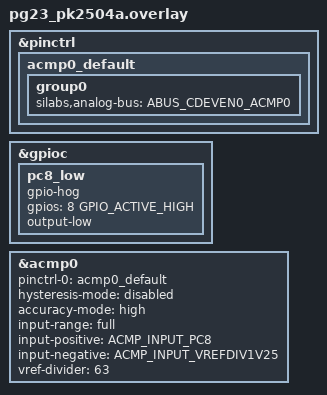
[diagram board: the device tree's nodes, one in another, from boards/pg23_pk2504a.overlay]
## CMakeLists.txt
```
# SPDX-License-Identifier: Apache-2.0

cmake_minimum_required(VERSION 3.20.0)

find_package(Zephyr REQUIRED HINTS $ENV{ZEPHYR_BASE})
project(comparator)

target_sources(app PRIVATE src/main.c)

zephyr_library_include_directories(${ZEPHYR_BASE}/samples/comparator)
```

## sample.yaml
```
sample:
  name: Comparator
  description: Similar to the Silabs' SOC Blinky sample, implements a simple custom
              GATT service controlling the state of the LED (ON/OFF)
              and sending notifications to subscribed clients when the button state changes.
tests:
  sample.comparator:
    harness: comparator
    integration_platforms:
      - xg24_dk2601b
    tags:
      - led
      - gpio
    build_only: true
```

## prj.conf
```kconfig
CONFIG_GPIO=y
CONFIG_PM_DEVICE=y
CONFIG_PM_DEVICE_RUNTIME=y
CONFIG_COMPARATOR=y
```

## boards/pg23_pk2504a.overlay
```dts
/*
 * Copyright (c) 2026 Silicon Laboratories Inc.
 *
 * SPDX-License-Identifier: Apache-2.0
 */

#include <zephyr/dt-bindings/gpio/gpio.h>
#include <zephyr/dt-bindings/comparator/silabs-acmp.h>
#include <zephyr/dt-bindings/pinctrl/silabs/xg23-pinctrl.h>

&pinctrl {
	acmp0_default: acmp0_default {
		group0 {
			silabs,analog-bus = <ABUS_CDEVEN0_ACMP0>;
		};
	};
};

&gpioc {
	pc8_low: pc8_low {
		gpio-hog;
		gpios = <8 GPIO_ACTIVE_HIGH>;
		output-low;
	};
};

&acmp0 {
	pinctrl-0 = <&acmp0_default>;
	pinctrl-names = "default";
	status = "okay";

	hysteresis-mode = "disabled";
	accuracy-mode = "high";
	input-range = "full";
	input-positive = <ACMP_INPUT_PC8>;
	input-negative = <ACMP_INPUT_VREFDIV1V25>;
	vref-divider = <63>;
};
```

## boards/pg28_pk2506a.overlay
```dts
/*
 * Copyright (c) 2026 Silicon Laboratories Inc.
 *
 * SPDX-License-Identifier: Apache-2.0
 */

#include <zephyr/dt-bindings/gpio/gpio.h>
#include <zephyr/dt-bindings/comparator/silabs-acmp.h>
#include <zephyr/dt-bindings/pinctrl/silabs/xg28-pinctrl.h>

&pinctrl {
	acmp0_default: acmp0_default {
		group0 {
			silabs,analog-bus = <ABUS_CDEVEN0_ACMP0>;
		};
	};
};

&gpioc {
	pc10_low: pc10_low {
		gpio-hog;
		gpios = <10 GPIO_ACTIVE_HIGH>;
		output-low;
	};
};

&acmp0 {
	pinctrl-0 = <&acmp0_default>;
	pinctrl-names = "default";
	status = "okay";

	hysteresis-mode = "disabled";
	accuracy-mode = "high";
	input-range = "full";
	input-positive = <ACMP_INPUT_PC10>;
	input-negative = <ACMP_INPUT_VREFDIV1V25>;
	vref-divider = <63>;
};
```

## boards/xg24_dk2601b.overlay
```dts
/*
 * Copyright (c) 2026 Silicon Laboratories Inc.
 *
 * SPDX-License-Identifier: Apache-2.0
 */

#include <zephyr/dt-bindings/gpio/gpio.h>
#include <zephyr/dt-bindings/comparator/silabs-acmp.h>
#include <zephyr/dt-bindings/pinctrl/silabs/xg24-pinctrl.h>

&pinctrl {
	acmp0_default: acmp0_default {
		group0 {
			silabs,analog-bus = <ABUS_CDODD0_ACMP0>;
		};
	};
};

&gpioc {
	pc3_low: pc3_low {
		gpio-hog;
		gpios = <3 GPIO_ACTIVE_HIGH>;
		output-low;
	};
};

&acmp0 {
	pinctrl-0 = <&acmp0_default>;
	pinctrl-names = "default";
	status = "okay";

	hysteresis-mode = "disabled";
	accuracy-mode = "high";
	input-range = "full";
	input-positive = <ACMP_INPUT_PC3>;
	input-negative = <ACMP_INPUT_VREFDIV1V25>;
	vref-divider = <63>;
};
```

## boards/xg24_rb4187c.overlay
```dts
/*
 * Copyright (c) 2026 Silicon Laboratories Inc.
 *
 * SPDX-License-Identifier: Apache-2.0
 */

#include <zephyr/dt-bindings/gpio/gpio.h>
#include <zephyr/dt-bindings/comparator/silabs-acmp.h>
#include <zephyr/dt-bindings/pinctrl/silabs/xg24-pinctrl.h>

&pinctrl {
	acmp0_default: acmp0_default {
		group0 {
			silabs,analog-bus = <ABUS_BEVEN0_ACMP0>;
		};
	};
};

&gpiob {
	pb2_low: pb2_low {
		gpio-hog;
		gpios = <2 GPIO_ACTIVE_HIGH>;
		output-low;
	};
};

&acmp0 {
	pinctrl-0 = <&acmp0_default>;
	pinctrl-names = "default";
	status = "okay";

	hysteresis-mode = "disabled";
	accuracy-mode = "high";
	input-range = "full";
	input-positive = <ACMP_INPUT_PB2>;
	input-negative = <ACMP_INPUT_VREFDIV1V25>;
	vref-divider = <63>;
};
```

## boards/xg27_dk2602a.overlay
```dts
/*
 * Copyright (c) 2026 Silicon Laboratories Inc.
 *
 * SPDX-License-Identifier: Apache-2.0
 */

#include <zephyr/dt-bindings/gpio/gpio.h>
#include <zephyr/dt-bindings/comparator/silabs-acmp.h>
#include <zephyr/dt-bindings/pinctrl/silabs/xg27-pinctrl.h>

&pinctrl {
	acmp0_default: acmp0_default {
		group0 {
			silabs,analog-bus = <ABUS_CDEVEN0_ACMP0>;
		};
	};
};

&gpioc {
	pc0_low: pc0_low {
		gpio-hog;
		gpios = <0 GPIO_ACTIVE_HIGH>;
		output-low;
	};
};

&acmp0 {
	pinctrl-0 = <&acmp0_default>;
	pinctrl-names = "default";
	status = "okay";

	hysteresis-mode = "disabled";
	accuracy-mode = "high";
	input-range = "full";
	input-positive = <ACMP_INPUT_PC0>;
	input-negative = <ACMP_INPUT_VREFDIV1V25>;
	vref-divider = <63>;
};
```

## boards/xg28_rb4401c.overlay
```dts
/*
 * Copyright (c) 2026 Silicon Laboratories Inc.
 *
 * SPDX-License-Identifier: Apache-2.0
 */

#include <zephyr/dt-bindings/gpio/gpio.h>
#include <zephyr/dt-bindings/comparator/silabs-acmp.h>
#include <zephyr/dt-bindings/pinctrl/silabs/xg28-pinctrl.h>

&pinctrl {
	acmp0_default: acmp0_default {
		group0 {
			silabs,analog-bus = <ABUS_CDEVEN0_ACMP0>;
		};
	};
};

&gpiod {
	pd4_low: pd4_low {
		gpio-hog;
		gpios = <4 GPIO_ACTIVE_HIGH>;
		output-low;
	};
};

&acmp0 {
	pinctrl-0 = <&acmp0_default>;
	pinctrl-names = "default";
	status = "okay";

	hysteresis-mode = "disabled";
	accuracy-mode = "high";
	input-range = "full";
	input-positive = <ACMP_INPUT_PD4>;
	input-negative = <ACMP_INPUT_VREFDIV1V25>;
	vref-divider = <63>;
};
```

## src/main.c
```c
/*
 * Copyright (c) 2026 Silicon Laboratories Inc.
 * Copyright (c) 2015-2016 Intel Corporation
 *
 * SPDX-License-Identifier: Apache-2.0
 */

#include <zephyr/device.h>
#include <zephyr/kernel.h>
#include <zephyr/drivers/comparator.h>
#include <zephyr/pm/device_runtime.h>
#include <zephyr/sys/printk.h>

static void acmp_cb(const struct device *dev, void *user_data)
{
	ARG_UNUSED(user_data);
	int out = comparator_get_output(dev);

	printk("Comparator triggered, output=%d\n", out);
}

int main(void)
{
	int ret;

	const struct device *cmp = DEVICE_DT_GET(DT_NODELABEL(acmp0));

	if (!device_is_ready(cmp)) {
		printk("ACMP device not ready\n");
		return 0;
	}

	ret = pm_device_runtime_get(cmp);
	if (ret < 0) {
		printk("pm_device_runtime_get failed: %d\n", ret);
		return 0;
	}

	/* Optional: read current comparator output */
	ret = comparator_get_output(cmp);
	if (ret < 0) {
		printk("comparator_get_output failed: %d\n", ret);
		return 0;
	}

	printk("Initial comparator output = %d\n", ret);

	/* Optional: enable edge trigger */
	ret = comparator_set_trigger(cmp, COMPARATOR_TRIGGER_BOTH_EDGES);
	if (ret < 0) {
		printk("comparator_set_trigger failed: %d\n", ret);
		return 0;
	}

	/* Optional: register callback */
	ret = comparator_set_trigger_callback(cmp, acmp_cb, NULL);
	if (ret < 0) {
		printk("comparator_set_trigger_callback failed: %d\n", ret);
		return 0;
	}

	while (1) {
		k_sleep(K_SECONDS(1));

		ret = comparator_get_output(cmp);
		if (ret >= 0) {
			printk("Comparator output = %d\n", ret);
		}

		ret = comparator_trigger_is_pending(cmp);
		if (ret > 0) {
			printk("Trigger was pending\n");
		}
	}

	return 0;
}
```
